# STM32U5A9 register map
File version: 1.7
CPU: CM33 r0p1, little endian, MPU, FPU, 4 interrupt priority bits
Registers are 32-bit, read-write, reset 0x0 unless marked. A register's access mark holds for its fields unless they carry their own. Offsets are from the block's base; [hi:lo] are bit positions; {n}, {i} and the like mark numbered series; 'fields as' and 'values as' point back to an identical list.

## RCC (part 1 of 2) — Reset and clock control
Base 0x46020C00
Same registers: SEC_RCC 0x56020C00
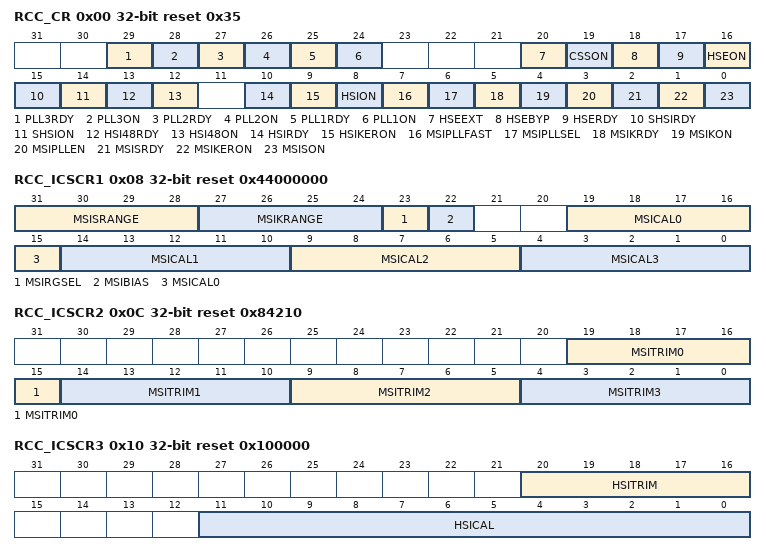
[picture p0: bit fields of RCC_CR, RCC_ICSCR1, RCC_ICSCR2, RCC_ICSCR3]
0x00 RCC_CR access per field reset 0x35 — RCC clock control register
  [29] PLL3RDY ro — PLL3 clock ready flag
    0=PLL3 unlocked; 1=PLL3 locked
  [28] PLL3ON rw — PLL3 enable
    0=PLL3 OFF; 1=PLL3 ON
  [27] PLL2RDY ro — PLL2 clock ready flag
    0=PLL2 unlocked; 1=PLL2 locked
  [26] PLL2ON rw — PLL2 enable
    0=PLL2 OFF; 1=PLL2 ON
  [25] PLL1RDY ro — PLL1 clock ready flag
    0=PLL1 unlocked; 1=PLL1 locked
  [24] PLL1ON rw — PLL1 enable
    0=PLL1 OFF; 1=PLL1 ON
  [20] HSEEXT rw — HSE external clock bypass mode
    0=external HSE clock analog mode; 1=external HSE clock digital mode (through I/O Schmitt trigger)
  [19] CSSON rw — Clock security system enable
    0=clock security system OFF (clock detector OFF); 1=clock security system ON (clock detector ON if the HSE oscillator is stable, OFF if not)
  [18] HSEBYP rw — HSE crystal oscillator bypass
    0=HSE crystal oscillator not bypassed; 1=HSE crystal oscillator bypassed with external clock
  [17] HSERDY ro — HSE clock ready flag
    0=HSE oscillator not ready; 1=HSE oscillator ready
  [16] HSEON rw — HSE clock enable
    0=HSE oscillator off; 1=HSE oscillator on
  [15] SHSIRDY ro — SHSI clock ready flag
    0=SHSI oscillator not ready; 1=SHSI oscillator ready
  [14] SHSION rw — SHSI clock enable
    0=SHSI oscillator off; 1=SHSI oscillator on
  [13] HSI48RDY ro — HSI48 clock ready flag
    0=HSI48 oscillator not ready; 1=HSI48 oscillator ready
  [12] HSI48ON rw — HSI48 clock enable
    0=HSI48 oscillator off; 1=HSI48 oscillator on
  [10] HSIRDY ro — HSI16 clock ready flag
    0=HSI16 oscillator not ready; 1=HSI16 oscillator ready
  [9] HSIKERON rw — HSI16 enable for some peripheral kernels
    0=No effect on HSI16 oscillator; 1=HSI16 oscillator forced on even in Stop mode
  [8] HSION rw — HSI16 clock enable
    0=HSI16 oscillator off; 1=HSI16 oscillator on
  [7] MSIPLLFAST rw — MSI PLL mode fast startup
    0=MSI PLL normal start-up; 1=MSI PLL fast start-up
  [6] MSIPLLSEL rw — MSI clock with PLL mode selection
    0=PLL mode applied to MSIK (MSI kernel) clock output; 1=PLL mode applied to MSIS (MSI system) clock output
  [5] MSIKRDY ro — MSIK clock ready flag
    0=MSIK (MSI kernel) oscillator not ready; 1=MSIK (MSI kernel) oscillator ready
  [4] MSIKON rw — MSIK clock enable
    0=MSIK (MSI kernel) oscillator disabled; 1=MSIK (MSI kernel) oscillator enabled
  [3] MSIPLLEN rw — MSI clock PLL-mode enable
    0=MSI PLL-mode OFF; 1=MSI PLL-mode ON
  [2] MSISRDY ro — MSIS clock ready flag
    0=MSIS (MSI system) oscillator not ready; 1=MSIS (MSI system) oscillator ready
  [1] MSIKERON rw — MSI enable for some peripheral kernels
    0=No effect on MSI oscillator; 1=MSI oscillator forced ON even in Stop mode
  [0] MSISON rw — MSIS clock enable
    0=MSIS (MSI system) oscillator off; 1=MSIS (MSI system) oscillator on
0x08 RCC_ICSCR1 access per field reset 0x44000000 (reset mask 0xFFF00000) — RCC internal clock sources calibration register 1
  [31:28] MSISRANGE rw — MSIS clock ranges
    0=range 0 around 48 MHz; 1=range 1 around 24 MHz; 2=range 2 around 16 MHz; 3=range 3 around 12 MHz; 4=range 4 around 4 MHz (reset value); 5=range 5 around 2 MHz; 6=range 6 around 1.33 MHz; 7=range 7 around 1 MHz; 8=range 8 around 3.072 MHz; 9=range 9 around 1.536 MHz; 10=range 10 around 1.024 MHz; 11=range 11 around 768 kHz; 12=range 12 around 400 kHz; 13=range 13 around 200 kHz; 14=range 14 around 133 kHz; 15=range 15 around 100 kHz
  [27:24] MSIKRANGE rw — MSIK clock ranges
    values as MSISRANGE
  [23] MSIRGSEL rw — MSI clock range selection
    0=MSIS/MSIK ranges provided by MSISSRANGE[3:0] and MSIKSRANGE[3:0] in RCC_CSR; 1=MSIS/MSIK ranges provided by MSISRANGE[3:0] and MSIKRANGE[3:0] in RCC_ICSCR1
  [22] MSIBIAS rw — MSI bias mode selection
    0=MSI bias continuous mode (clock accuracy fast settling time); 1=MSI bias sampling mode when the regulator is in range 4, or when the device is in Stop 1 or Stop 2 (ultra-low-power mode)
  [19-5n:15-5n] MSICAL{n} ro (n=0..3) — MSIRC{n} clock calibration for MSI ranges {4n} to {4n+3}
0x0C RCC_ICSCR2 reset 0x84210 — RCC internal clock sources calibration register 2
  [19-5n:15-5n] MSITRIM{n} (n=0..3) — MSI clock trimming for ranges {4n} to {4n+3}
0x10 RCC_ICSCR3 access per field reset 0x100000 (reset mask 0xFFFFF000) — RCC internal clock sources calibration register 3
  [20:16] HSITRIM rw — HSI clock trimming
  [11:0] HSICAL ro — HSI clock calibration
0x14 RCC_CRRCR ro (reset mask 0xFFFFF000) — RCC clock recovery RC register
  [8:0] HSI48CAL — HSI48 clock calibration
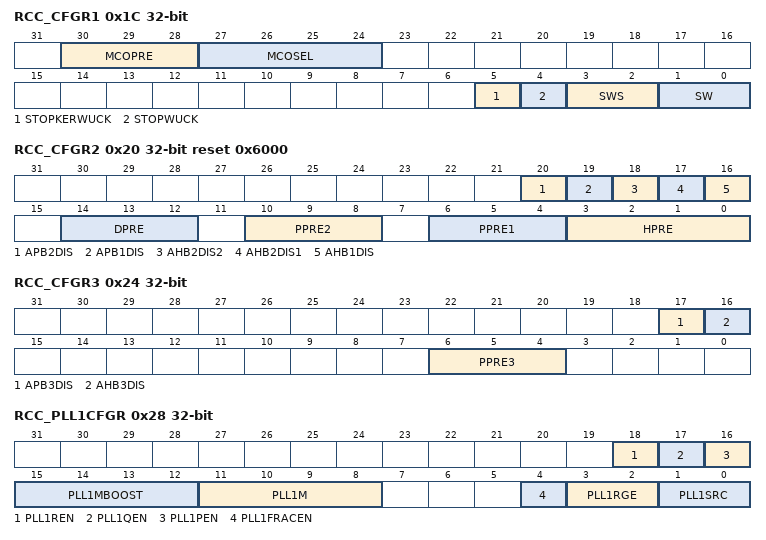
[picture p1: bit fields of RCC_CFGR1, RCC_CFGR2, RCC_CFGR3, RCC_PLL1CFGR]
0x1C RCC_CFGR1 access per field — RCC clock configuration register 1
  [30:28] MCOPRE rw — microcontroller clock output prescaler
    0=MCO divided by 1; 1=MCO divided by 2; 2=MCO divided by 4; 3=MCO divided by 8; 4=MCO divided by 16
  [27:24] MCOSEL rw — microcontroller clock output
    0=MCO output disabled, no clock on MCO; 1=SYSCLK system clock selected; 2=MSIS clock selected; 3=HSI16 clock selected; 4=HSE clock selected; 5=Main PLL clock pll1_r_ck selected; 6=LSI clock selected; 7=LSE clock selected; 8=Internal HSI48 clock selected; 9=MSIK clock selected
  [5] STOPKERWUCK rw — wake-up from Stop kernel clock automatic enable selection
    0=MSIK oscillator automatically enabled when exiting Stop mode; 1=HSI16 oscillator automatically enabled when exiting Stop mode
  [4] STOPWUCK rw — wake-up from Stop and CSS backup clock selection
    0=MSIS oscillator selected as wake-up from stop clock and CSS backup clock; 1=HSI16 oscillator selected as wake-up from stop clock and CSS backup clock
  [3:2] SWS ro — system clock switch status
    0=MSIS oscillator used as system clock; 1=HSI16 oscillator used as system clock; 2=HSE used as system clock; 3=PLL pll1_r_ck used as system clock
  [1:0] SW rw — system clock switch
    0=MSIS selected as system clock; 1=HSI16 selected as system clock; 2=HSE selected as system clock; 3=PLL pll1_r_ck selected as system clock
0x20 RCC_CFGR2 reset 0x6000 — RCC clock configuration register 2
  [20] APB2DIS — APB2 clock disable
    0=APB2 clock enabled, distributed to peripherals according to their dedicated clock enable control bits; 1=APB2 clock disabled
  [19] APB1DIS — APB1 clock disable
    0=APB1 clock enabled, distributed to peripherals according to their dedicated clock enable control bits; 1=APB1 clock disabled
  [18] AHB2DIS2 — AHB2_2 clock disable
    0=AHB2_2 clock enabled, distributed to peripherals according to their dedicated clock enable control bits; 1=AHB2_2 clock disabled
  [17] AHB2DIS1 — AHB2_1 clock disable
    0=AHB2_1 clock enabled, distributed to peripherals according to their dedicated clock enable control bits; 1=AHB2_1 clock disabled
  [16] AHB1DIS — AHB1 clock disable
    0=AHB1 clock enabled, distributed to peripherals according to their dedicated clock enable control bits; 1=AHB1 clock disabled
  [14:12] DPRE — DSI PHY prescaler
    4=DCLK divided by 2; 5=DCLK divided by 4; 6=DCLK divided by 8; 7=DCLK divided by 16
  [10:8] PPRE2 — APB2 prescaler
    4=PCLK2 divided by 2; 5=PCLK2 divided by 4; 6=PCLK2 divided by 8; 7=PCLK2 divided by 16
  [6:4] PPRE1 — APB1 prescaler
    4=PCLK1 divided by 2; 5=PCLK1 divided by 4; 6=PCLK1 divided by 8; 7=PCLK1 divided by 16
  [3:0] HPRE — AHB prescaler
    8=SYSCLK divided by 2; 9=SYSCLK divided by 4; 10=SYSCLK divided by 8; 11=SYSCLK divided by 16; 12=SYSCLK divided by 64; 13=SYSCLK divided by 128; 14=SYSCLK divided by 256; 15=SYSCLK divided by 512
0x24 RCC_CFGR3 — RCC clock configuration register 3
  [17] APB3DIS — APB3 clock disable
    0=APB3 clock enabled, distributed to peripherals according to their dedicated clock enable control bits; 1=APB3 clock disabled
  [16] AHB3DIS — AHB3 clock disable
    0=AHB3 clock enabled, distributed to peripherals according to their dedicated clock enable control bits; 1=AHB3 clock disabled
  [6:4] PPRE3 — APB3 prescaler
    4=HCLK divided by 2; 5=HCLK divided by 4; 6=HCLK divided by 8; 7=HCLK divided by 16
0x28 RCC_PLL1CFGR — RCC PLL1 configuration register
  [18] PLL1REN — PLL1 DIVR divider output enable
    0=pll1_r_ck output disabled; 1=pll1_r_ck output enabled
  [17] PLL1QEN — PLL1 DIVQ divider output enable
    0=pll1_q_ck output disabled; 1=pll1_q_ck output enabled
  [16] PLL1PEN — PLL1 DIVP divider output enable
    0=pll1_p_ck output disabled; 1=pll1_p_ck output enabled
  [15:12] PLL1MBOOST — Prescaler for EPOD booster input clock
    0=division by 1 (bypass); 1=division by 2; 2=division by 4; 3=division by 6; 4=division by 8; 5=division by 10; 6=division by 12; 7=division by 14; 8=division by 16
  [11:8] PLL1M — Prescaler for PLL1
    0=division by 1 (bypass); 1=division by 2; 2=division by 3; 15=division by 16
  [4] PLL1FRACEN — PLL1 fractional latch enable
  [3:2] PLL1RGE — PLL1 input frequency range
    3=PLL1 input (ref1_ck) clock range frequency between 8 and 16 MHz
  [1:0] PLL1SRC — PLL1 entry clock source
    0=No clock sent to PLL1; 1=MSIS clock selected as PLL1 clock entry; 2=HSI16 clock selected as PLL1 clock entry; 3=HSE clock selected as PLL1 clock entry
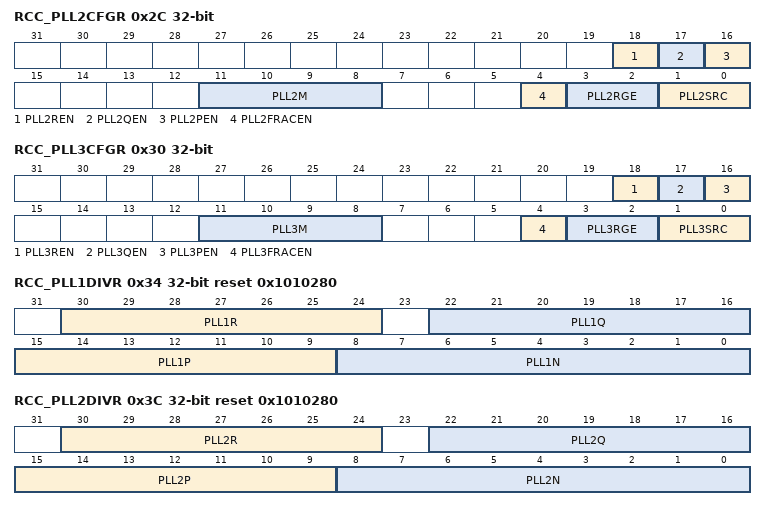
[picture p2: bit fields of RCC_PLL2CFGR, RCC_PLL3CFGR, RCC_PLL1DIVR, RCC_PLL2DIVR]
0x2C RCC_PLL2CFGR — RCC PLL2 configuration register
  [18] PLL2REN — PLL2 DIVR divider output enable
    0=pll2_r_ck output disabled; 1=pll2_r_ck output enabled
  [17] PLL2QEN — PLL2 DIVQ divider output enable
    0=pll2_q_ck output disabled; 1=pll2_q_ck output enabled
  [16] PLL2PEN — PLL2 DIVP divider output enable
    0=pll2_p_ck output disabled; 1=pll2_p_ck output enabled
  [11:8] PLL2M — Prescaler for PLL2
    values as RCC_PLL1CFGR.PLL1M
  [4] PLL2FRACEN — PLL2 fractional latch enable
  [3:2] PLL2RGE — PLL2 input frequency range
    3=PLL2 input (ref2_ck) clock range frequency between 8 and 16 MHz
  [1:0] PLL2SRC — PLL2 entry clock source
    0=No clock sent to PLL2; 1=MSIS clock selected as PLL2 clock entry; 2=HSI16 clock selected as PLL2 clock entry; 3=HSE clock selected as PLL2 clock entry
0x30 RCC_PLL3CFGR — RCC PLL3 configuration register
  [18] PLL3REN — PLL3 DIVR divider output enable
    0=pll3_r_ck output disabled; 1=pll3_r_ck output enabled
  [17] PLL3QEN — PLL3 DIVQ divider output enable
    0=pll3_q_ck output disabled; 1=pll3_q_ck output enabled
  [16] PLL3PEN — PLL3 DIVP divider output enable
    0=pll3_p_ck output disabled; 1=pll3_p_ck output enabled
  [11:8] PLL3M — Prescaler for PLL3
    values as RCC_PLL1CFGR.PLL1M
  [4] PLL3FRACEN — PLL3 fractional latch enable
  [3:2] PLL3RGE — PLL3 input frequency range
    3=PLL3 input (ref3_ck) clock range frequency between 8 and 16 MHz
  [1:0] PLL3SRC — PLL3 entry clock source
    0=No clock sent to PLL3; 1=MSIS clock selected as PLL3 clock entry; 2=HSI16 clock selected as PLL3 clock entry; 3=HSE clock selected as PLL3 clock entry
0x34 RCC_PLL1DIVR reset 0x1010280 — RCC PLL1 dividers register
  [30:24] PLL1R — PLL1 DIVR division factor
    0=Not allowed; 1=pll1_r_ck = vco1_ck / 2 (default after reset); 2=pll1_r_ck = vco1_ck / 3; 3=pll1_r_ck = vco1_ck / 4; 127=pll1_r_ck = vco1_ck / 128
  [22:16] PLL1Q — PLL1 DIVQ division factor
    0=pll1_q_ck = vco1_ck; 1=pll1_q_ck = vco1_ck / 2 (default after reset); 2=pll1_q_ck = vco1_ck / 3; 3=pll1_q_ck = vco1_ck / 4; 127=pll1_q_ck = vco1_ck / 128
  [15:9] PLL1P — PLL1 DIVP division factor
    0=Not allowed; 1=pll1_p_ck = vco1_ck / 2 (default after reset); 2=pll1_p_ck = vco1_ck; 3=pll1_p_ck = vco1_ck / 4; 127=pll1_p_ck = vco1_ck / 128
  [8:0] PLL1N — Multiplication factor for PLL1 VCO
    3=PLL1N = 4; 4=PLL1N = 5; 5=PLL1N = 6; 128=PLL1N = 129 (default after reset); 0x1FF=PLL1N = 512
{0x30+8i} RCC_PLL{i}FRACR (i=1..3) — RCC PLL{i} fractional divider register
  [15:3] PLL{i}FRACN — Fractional part of the multiplication factor for PLL{i} VCO
0x3C RCC_PLL2DIVR reset 0x1010280 — RCC PLL2 dividers configuration register
  [30:24] PLL2R — PLL2 DIVR division factor
    0=pll2_r_ck = vco2_ck; 1=pll2_r_ck = vco2_ck / 2 (default after reset); 2=pll2_r_ck = vco2_ck / 3; 3=pll2_r_ck = vco2_ck / 4; 127=pll2_r_ck = vco2_ck / 128
  [22:16] PLL2Q — PLL2 DIVQ division factor
    0=pll2_q_ck = vco2_ck; 1=pll2_q_ck = vco2_ck / 2 (default after reset); 2=pll2_q_ck = vco2_ck / 3; 3=pll2_q_ck = vco2_ck / 4; 127=pll2_q_ck = vco2_ck / 128
  [15:9] PLL2P — PLL2 DIVP division factor
    0=pll2_p_ck = vco2_ck; 1=pll2_p_ck = vco2_ck / 2 (default after reset); 2=pll2_p_ck = vco2_ck / 3; 3=pll2_p_ck = vco2_ck / 4; 127=pll2_p_ck = vco2_ck / 128
  [8:0] PLL2N — Multiplication factor for PLL2 VCO
    3=PLL2N = 4; 4=PLL2N = 5; 5=PLL2N = 6; 128=PLL2N = 129 (default after reset); 0x1FF=PLL2N = 512
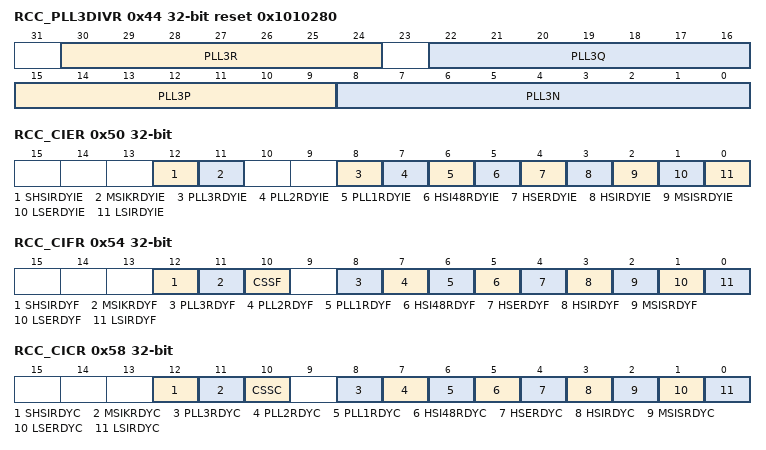
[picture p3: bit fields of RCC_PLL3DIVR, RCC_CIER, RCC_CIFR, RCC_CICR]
0x44 RCC_PLL3DIVR reset 0x1010280 — RCC PLL3 dividers configuration register
  [30:24] PLL3R — PLL3 DIVR division factor
    0=pll3_r_ck = vco3_ck; 1=pll3_r_ck = vco3_ck / 2 (default after reset); 2=pll3_r_ck = vco3_ck / 3; 3=pll3_r_ck = vco3_ck / 4; 127=pll3_r_ck = vco3_ck / 128
  [22:16] PLL3Q — PLL3 DIVQ division factor
    0=pll3_q_ck = vco3_ck; 1=pll3_q_ck = vco3_ck / 2 (default after reset); 2=pll3_q_ck = vco3_ck / 3; 3=pll3_q_ck = vco3_ck / 4; 127=pll3_q_ck = vco3_ck / 128
  [15:9] PLL3P — PLL3 DIVP division factor
    0=pll3_p_ck = vco3_ck; 1=pll3_p_ck = vco3_ck / 2 (default after reset); 2=pll3_p_ck = vco3_ck / 3; 3=pll3_p_ck = vco3_ck / 4; 127=pll3_p_ck = vco3_ck / 128
  [8:0] PLL3N — Multiplication factor for PLL3 VCO
    3=PLL3N = 4; 4=PLL3N = 5; 5=PLL3N = 6; 128=PLL3N = 129 (default after reset); 0x1FF=PLL3N = 512
0x50 RCC_CIER — RCC clock interrupt enable register
  [12] SHSIRDYIE — SHSI ready interrupt enable
    0=SHSI ready interrupt disabled; 1=SHSI ready interrupt enabled
  [11] MSIKRDYIE — MSIK ready interrupt enable
    0=MSIK ready interrupt disabled; 1=MSIK ready interrupt enabled
  [8] PLL3RDYIE — PLL3 ready interrupt enable
    0=PLL3 lock interrupt disabled; 1=PLL3 lock interrupt enabled
  [7] PLL2RDYIE — PLL2 ready interrupt enable
    0=PLL2 lock interrupt disabled; 1=PLL2 lock interrupt enabled
  [6] PLL1RDYIE — PLL ready interrupt enable
    0=PLL1 lock interrupt disabled; 1=PLL1 lock interrupt enabled
  [5] HSI48RDYIE — HSI48 ready interrupt enable
    0=HSI48 ready interrupt disabled; 1=HSI48 ready interrupt enabled
  [4] HSERDYIE — HSE ready interrupt enable
    0=HSE ready interrupt disabled; 1=HSE ready interrupt enabled
  [3] HSIRDYIE — HSI16 ready interrupt enable
    0=HSI16 ready interrupt disabled; 1=HSI16 ready interrupt enabled
  [2] MSISRDYIE — MSIS ready interrupt enable
    0=MSIS ready interrupt disabled; 1=MSIS ready interrupt enabled
  [1] LSERDYIE — LSE ready interrupt enable
    0=LSE ready interrupt disabled; 1=LSE ready interrupt enabled
  [0] LSIRDYIE — LSI ready interrupt enable
    0=LSI ready interrupt disabled; 1=LSI ready interrupt enabled
0x54 RCC_CIFR ro — RCC clock interrupt flag register
  [12] SHSIRDYF — SHSI ready interrupt flag
    0=No clock ready interrupt caused by the SHSI oscillator; 1=Clock ready interrupt caused by the SHSI oscillator
  [11] MSIKRDYF — MSIK ready interrupt flag
    0=No clock ready interrupt caused by the MSIK oscillator; 1=Clock ready interrupt caused by the MSIK oscillator
  [10] CSSF — Clock security system interrupt flag
    0=No clock security interrupt caused by HSE clock failure; 1=Clock security interrupt caused by HSE clock failure
  [8] PLL3RDYF — PLL3 ready interrupt flag
    0=No clock ready interrupt caused by PLL3 lock; 1=Clock ready interrupt caused by PLL3 lock
  [7] PLL2RDYF — PLL2 ready interrupt flag
    0=No clock ready interrupt caused by PLL2 lock; 1=Clock ready interrupt caused by PLL2 lock
  [6] PLL1RDYF — PLL1 ready interrupt flag
    0=No clock ready interrupt caused by PLL1 lock; 1=Clock ready interrupt caused by PLL1 lock
  [5] HSI48RDYF — HSI48 ready interrupt flag
    0=No clock ready interrupt caused by the HSI48 oscillator; 1=Clock ready interrupt caused by the HSI48 oscillator
  [4] HSERDYF — HSE ready interrupt flag
    0=No clock ready interrupt caused by the HSE oscillator; 1=Clock ready interrupt caused by the HSE oscillator
  [3] HSIRDYF — HSI16 ready interrupt flag
    0=No clock ready interrupt caused by the HSI16 oscillator; 1=Clock ready interrupt caused by the HSI16 oscillator
  [2] MSISRDYF — MSIS ready interrupt flag
    0=No clock ready interrupt caused by the MSIS oscillator; 1=Clock ready interrupt caused by the MSIS oscillator
  [1] LSERDYF — LSE ready interrupt flag
    0=No clock ready interrupt caused by the LSE oscillator; 1=Clock ready interrupt caused by the LSE oscillator
  [0] LSIRDYF — LSI ready interrupt flag
    0=No clock ready interrupt caused by the LSI oscillator; 1=Clock ready interrupt caused by the LSI oscillator
0x58 RCC_CICR wo — RCC clock interrupt clear register
  [12] SHSIRDYC — SHSI oscillator ready interrupt clear
  [11] MSIKRDYC — MSIK oscillator ready interrupt clear
  [10] CSSC — Clock security system interrupt clear
  [8] PLL3RDYC — PLL3 ready interrupt clear
  [7] PLL2RDYC — PLL2 ready interrupt clear
  [6] PLL1RDYC — PLL1 ready interrupt clear
  [5] HSI48RDYC — HSI48 ready interrupt clear
  [4] HSERDYC — HSE ready interrupt clear
  [3] HSIRDYC — HSI16 ready interrupt clear
  [2] MSISRDYC — MSIS ready interrupt clear
  [1] LSERDYC — LSE ready interrupt clear
  [0] LSIRDYC — LSI ready interrupt clear
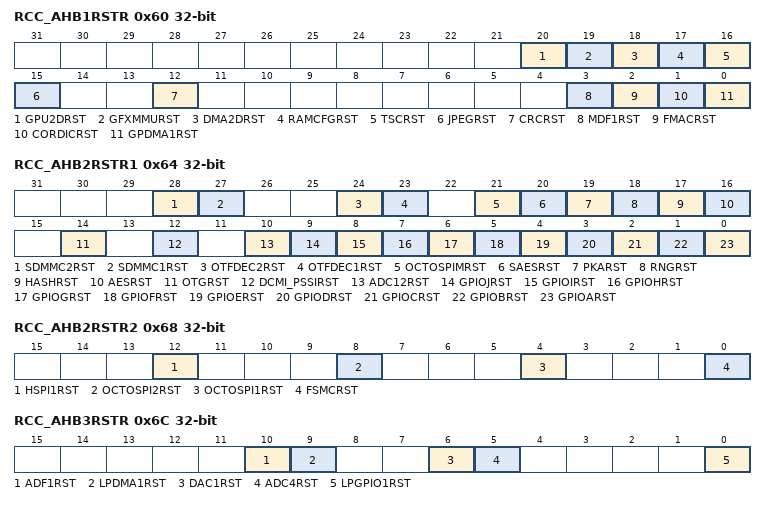
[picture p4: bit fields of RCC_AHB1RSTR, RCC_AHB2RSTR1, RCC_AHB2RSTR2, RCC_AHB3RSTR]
0x60 RCC_AHB1RSTR — RCC AHB1 peripheral reset register
  [20] GPU2DRST — GPU2D reset
    0=No effect; 1=Reset the GPU2D
  [19] GFXMMURST — GFXMMU reset
    0=No effect; 1=Reset the GFXMMU
  [18] DMA2DRST — DMA2D reset
    0=No effect; 1=Reset the DMA2D
  [17] RAMCFGRST — RAMCFG reset
    0=No effect; 1=Reset the RAMCFG
  [16] TSCRST — TSC reset
    0=No effect; 1=Reset the TSC
  [15] JPEGRST — JPEG reset
    0=No effect; 1=Reset the JPEG
  [12] CRCRST — CRC reset
    0=No effect; 1=Reset the CRC
  [3] MDF1RST — MDF1 reset
    0=No effect; 1=Reset the MDF1
  [2] FMACRST — FMAC reset
    0=No effect; 1=Reset the FMAC
  [1] CORDICRST — CORDIC reset
    0=No effect; 1=Reset the CORDIC
  [0] GPDMA1RST — GPDMA1 reset
    0=No effect; 1=Reset the GPDMA1
0x64 RCC_AHB2RSTR1 — RCC AHB2 peripheral reset register 1
  [28] SDMMC2RST — SDMMC2 reset
    0=No effect; 1=Reset the SDMMC2
  [27] SDMMC1RST — SDMMC1 reset
    0=No effect; 1=Reset the SDMMC1
  [24] OTFDEC2RST — OTFDEC2 reset
    0=No effect; 1=Reset the OTFDEC2
  [23] OTFDEC1RST — OTFDEC1 reset
    0=No effect; 1=Reset the OTFDEC1
  [21] OCTOSPIMRST — OCTOSPIM reset
    0=No effect; 1=Reset the OCTOSPIM
  [20] SAESRST — SAES hardware accelerator reset
    0=No effect; 1=Reset the SAES
  [19] PKARST — PKA reset
    0=No effect; 1=Reset the PKA
  [18] RNGRST — RNG reset
    0=No effect; 1=Reset the RNG
  [17] HASHRST — HASH reset
    0=No effect; 1=Reset the HASH
  [16] AESRST — AES hardware accelerator reset
    0=No effect; 1=Reset the AES
  [14] OTGRST — OTG_FS or OTG_HS reset
    0=No effect; 1=Reset the OTG_FS or OTG_HS
  [12] DCMI_PSSIRST — DCMI and PSSI reset
    0=No effect; 1=Reset the DCMI and PSSI
  [10] ADC12RST — ADC1 and ADC2 reset
    0=No effect; 1=Reset the ADC1 and ADC2
  [9] GPIOJRST — I/O port J reset
    0=No effect; 1=Reset the I/O port J
  [8] GPIOIRST — I/O port I reset
    0=No effect; 1=Reset the I/O port .I
  [7] GPIOHRST — I/O port H reset
    0=No effect; 1=Reset the I/O port H
  [6] GPIOGRST — I/O port G reset
    0=No effect; 1=Reset the I/O port G
  [5] GPIOFRST — I/O port F reset
    0=No effect; 1=Reset I/O port F
  [4] GPIOERST — I/O port E reset
    0=No effect; 1=Reset the I/O port E
  [3] GPIODRST — I/O port D reset
    0=No effect; 1=Reset the I/O port D
  [2] GPIOCRST — I/O port C reset
    0=No effect; 1=Reset the I/O port C
  [1] GPIOBRST — I/O port B reset
    0=No effect; 1=Reset the I/O port B
  [0] GPIOARST — I/O port A reset
    0=No effect; 1=Reset the I/O port A
0x68 RCC_AHB2RSTR2 — RCC AHB2 peripheral reset register 2
  [12] HSPI1RST — HSPI1 reset
    0=No effect; 1=Reset the HSPI1
  [8] OCTOSPI2RST — OCTOSPI2 reset
    0=No effect; 1=Reset the OCTOSPI2
  [4] OCTOSPI1RST — OCTOSPI1 reset
    0=No effect; 1=Reset the OCTOSPI1
  [0] FSMCRST — Flexible memory controller reset
    0=No effect; 1=Reset the FSMC
0x6C RCC_AHB3RSTR — RCC AHB3 peripheral reset register
  [10] ADF1RST — ADF1 reset
    0=No effect; 1=Reset the ADF1
  [9] LPDMA1RST — LPDMA1 reset
    0=No effect; 1=Reset the LPDMA1
  [6] DAC1RST — DAC1 reset
    0=No effect; 1=Reset the DAC1
  [5] ADC4RST — ADC4 reset
    0=No effect; 1=Reset the ADC4 interface
  [0] LPGPIO1RST — LPGPIO1 reset
    0=No effect; 1=Reset the LPGPIO1
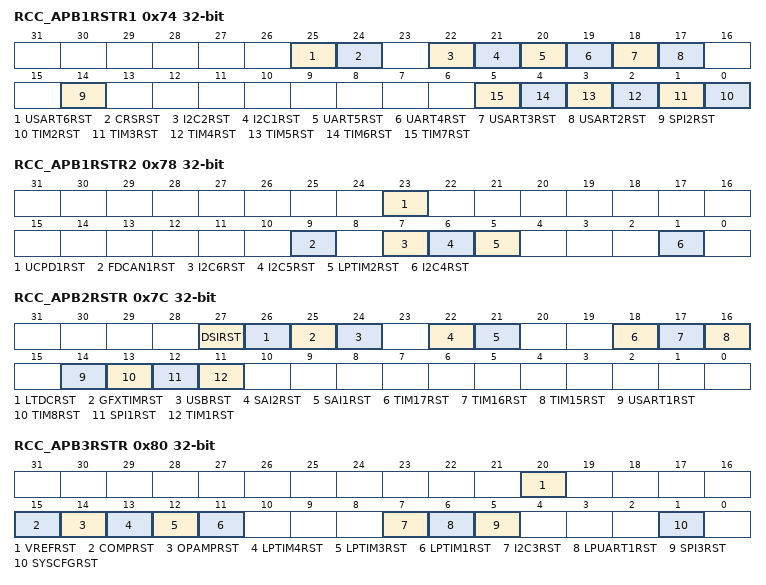
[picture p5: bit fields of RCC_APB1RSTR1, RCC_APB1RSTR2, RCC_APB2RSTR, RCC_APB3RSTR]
0x74 RCC_APB1RSTR1 — RCC APB1 peripheral reset register 1
  [25] USART6RST — USART6 reset
    0=No effect; 1=Reset the USART6
  [24] CRSRST — CRS reset
    0=No effect; 1=Reset the CRS
  [22] I2C2RST — I2C2 reset
    0=No effect; 1=Reset the I2C2
  [21] I2C1RST — I2C1 reset
    0=No effect; 1=Reset the I2C1
  [20] UART5RST — UART5 reset
    0=No effect; 1=Reset the UART5
  [19] UART4RST — UART4 reset
    0=No effect; 1=Reset the UART4
  [18] USART3RST — USART3 reset
    0=No effect; 1=Reset the USART3
  [17] USART2RST — USART2 reset
    0=No effect; 1=Reset the USART2
  [14] SPI2RST — SPI2 reset
    0=No effect; 1=Reset the SPI2
  [n-2] TIM{n}RST (n=2..7) — TIM{n} reset
    0=No effect; 1=Reset the TIM{n}
0x78 RCC_APB1RSTR2 — RCC APB1 peripheral reset register 2
  [23] UCPD1RST — UCPD1 reset
    0=No effect; 1=Reset the UCPD1
  [9] FDCAN1RST — FDCAN1 reset
    0=No effect; 1=Reset the FDCAN1
  [7] I2C6RST — I2C6 reset
    0=No effect; 1=Reset the I2C6
  [6] I2C5RST — I2C5 reset
    0=No effect; 1=Reset the I2C5
  [5] LPTIM2RST — LPTIM2 reset
    0=No effect; 1=Reset the LPTIM2
  [1] I2C4RST — I2C4 reset
    0=No effect; 1=Reset the I2C4
0x7C RCC_APB2RSTR — RCC APB2 peripheral reset register
  [27] DSIRST — DSI reset
    0=No effect; 1=Reset the DSI
  [26] LTDCRST — LTDC reset
    0=No effect; 1=Reset the LTDC
  [25] GFXTIMRST — GFXTIM reset
    0=No effect; 1=Reset the GFXTIM
  [24] USBRST — USB reset
    0=No effect; 1=Reset the USB
  [22] SAI2RST — SAI2 reset
    0=No effect; 1=Reset the SAI2
  [21] SAI1RST — SAI1 reset
    0=No effect; 1=Reset the SAI1
  [18] TIM17RST — TIM17 reset
    0=No effect; 1=Reset the TIM17
  [17] TIM16RST — TIM16 reset
    0=No effect; 1=Reset the TIM16
  [16] TIM15RST — TIM15 reset
    0=No effect; 1=Reset the TIM15
  [14] USART1RST — USART1 reset
    0=No effect; 1=Reset the USART1
  [13] TIM8RST — TIM8 reset
    0=No effect; 1=Reset the TIM8
  [12] SPI1RST — SPI1 reset
    0=No effect; 1=Reset the SPI1
  [11] TIM1RST — TIM1 reset
    0=No effect; 1=Reset the TIM1
0x80 RCC_APB3RSTR — RCC APB3 peripheral reset register
  [20] VREFRST — VREFBUF reset
    0=No effect; 1=Reset the VREFBUF
  [15] COMPRST — COMP reset
    0=No effect; 1=Reset the COMP
  [14] OPAMPRST — OPAMP reset
    0=No effect; 1=Reset the OPAMP
  [13] LPTIM4RST — LPTIM4 reset
    0=No effect; 1=Reset the LPTIM4
  [12] LPTIM3RST — LPTIM3 reset
    0=No effect; 1=Reset the LPTIM3
  [11] LPTIM1RST — LPTIM1 reset
    0=No effect; 1=Reset the LPTIM1
  [7] I2C3RST — I2C3 reset
    0=No effect; 1=Reset the I2C3
  [6] LPUART1RST — LPUART1 reset
    0=No effect; 1=Reset the LPUART1
  [5] SPI3RST — SPI3 reset
    0=No effect; 1=Reset the SPI3
  [1] SYSCFGRST — SYSCFG reset
    0=No effect; 1=Reset the SYSCFG
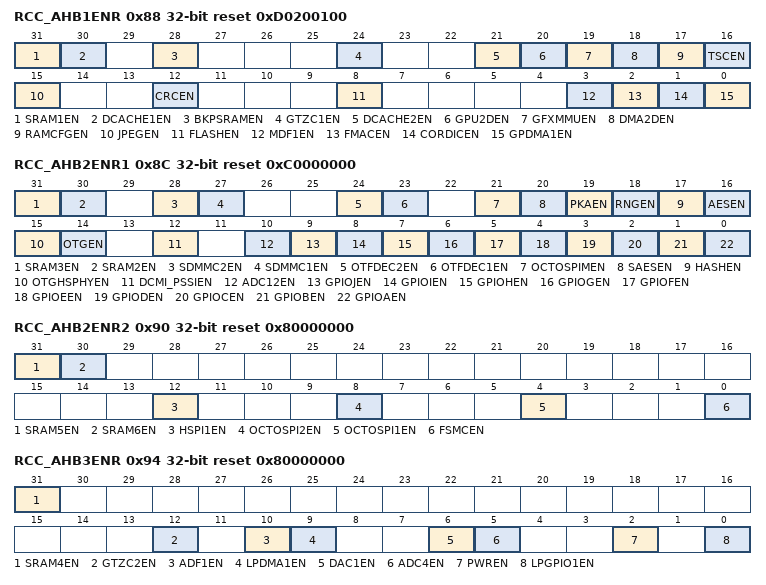
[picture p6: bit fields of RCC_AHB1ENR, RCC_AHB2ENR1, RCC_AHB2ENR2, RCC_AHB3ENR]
0x88 RCC_AHB1ENR reset 0xD0200100 — RCC AHB1 peripheral clock enable register
  [31] SRAM1EN — SRAM1 clock enable
    0=SRAM1 clock disabled; 1=SRAM1 clock enabled
  [30] DCACHE1EN — DCACHE1 clock enable
    0=DCACHE1 clock disabled; 1=DCACHE1 clock enabled
  [28] BKPSRAMEN — BKPSRAM clock enable
    0=BKPSRAM clock disabled; 1=BKPSRAM clock enabled
  [24] GTZC1EN — GTZC1 clock enable
    0=GTZC1 clock disabled; 1=GTZC1 clock enabled
  [21] DCACHE2EN — DCACHE2 clock enable
    0=DCACHE2 clock disabled; 1=DCACHE2 clock enabled
  [20] GPU2DEN — GPU2D clock enable
    0=GPU2D clock disabled; 1=GPU2D clock enabled
  [19] GFXMMUEN — GFXMMU clock enable
    0=GFXMMU clock disabled; 1=GFXMMU clock enabled
  [18] DMA2DEN — DMA2D clock enable
    0=DMA2D clock disabled; 1=DMA2D clock enabled
  [17] RAMCFGEN — RAMCFG clock enable
    0=RAMCFG clock disabled; 1=RAMCFG clock enabled
  [16] TSCEN — Touch sensing controller clock enable
    0=TSC clock disabled; 1=TSC clock enabled
  [15] JPEGEN — JPEG clock enable
    0=JPEG clock disabled; 1=JPEG clock enabled
  [12] CRCEN — CRC clock enable
    0=CRC clock disabled; 1=CRC clock enabled
  [8] FLASHEN — FLASH clock enable
    0=FLASH clock disabled; 1=FLASH clock enabled
  [3] MDF1EN — MDF1 clock enable
    0=MDF1 clock disabled; 1=MDF1 clock enabled
  [2] FMACEN — FMAC clock enable
    0=FMAC clock disabled; 1=FMAC clock enabled
  [1] CORDICEN — CORDIC clock enable
    0=CORDIC clock disabled; 1=CORDIC clock enabled
  [0] GPDMA1EN — GPDMA1 clock enable
    0=GPDMA1 clock disabled; 1=GPDMA1 clock enabled
0x8C RCC_AHB2ENR1 reset 0xC0000000 — RCC AHB2 peripheral clock enable register 1
  [31] SRAM3EN — SRAM3 clock enable
    0=SRAM3 clock disabled; 1=SRAM3 clock enabled
  [30] SRAM2EN — SRAM2 clock enable
    0=SRAM2 clock disabled; 1=SRAM2 clock enabled
  [28] SDMMC2EN — SDMMC2 clock enable
    0=SDMMC2 clock disabled; 1=SDMMC2 clock enabled
  [27] SDMMC1EN — SDMMC1 clock enable
    0=SDMMC1 clock disabled; 1=SDMMC1 clock enabled
  [24] OTFDEC2EN — OTFDEC2 clock enable
    0=OTFDEC2 clock disabled; 1=OTFDEC2 clock enabled
  [23] OTFDEC1EN — OTFDEC1 clock enable
    0=OTFDEC1 clock disabled; 1=OTFDEC1 clock enabled
  [21] OCTOSPIMEN — OCTOSPIM clock enable
    0=OCTOSPIM clock disabled; 1=OCTOSPIM clock enabled
  [20] SAESEN — SAES clock enable
    0=SAES clock disabled; 1=SAES clock enabled
  [19] PKAEN — PKA clock enable
    0=PKA clock disabled; 1=PKA clock enabled
  [18] RNGEN — RNG clock enable
    0=RNG clock disabled; 1=RNG clock enabled
  [17] HASHEN — HASH clock enable
    0=HASH clock disabled; 1=HASH clock enabled
  [16] AESEN — AES clock enable
    0=AES clock disabled; 1=AES clock enabled
  [15] OTGHSPHYEN — OTG_HS PHY clock enable
    0=OTG_HS PHY clock disabled; 1=OTG_HS PHY clock enabled
  [14] OTGEN — OTG_FS or OTG_HS clock enable
    0=OTG_FS or OTG_HS clock disabled; 1=OTG_FS or OTG_HS clock enabled
  [12] DCMI_PSSIEN — DCMI and PSSI clock enable
    0=DCMI and PSSI clock disabled; 1=DCMI and PSSI clock enabled
  [10] ADC12EN — ADC1 and ADC2 clock enable
    0=ADC1 and ADC2 clock disabled; 1=ADC1 and ADC2 clock enabled
  [9] GPIOJEN — I/O port J clock enable
    0=I/O port J clock disabled; 1=I/O port J clock enabled
  [8] GPIOIEN — I/O port I clock enable
    0=I/O port I clock disabled; 1=I/O port I clock enabled
  [7] GPIOHEN — I/O port H clock enable
    0=I/O port H clock disabled; 1=I/O port H clock enabled
  [6] GPIOGEN — I/O port G clock enable
    0=I/O port G clock disabled; 1=I/O port G clock enabled
  [5] GPIOFEN — I/O port F clock enable
    0=I/O port F clock disabled; 1=I/O port F clock enabled
  [4] GPIOEEN — I/O port E clock enable
    0=I/O port E clock disabled; 1=I/O port E clock enabled
  [3] GPIODEN — I/O port D clock enable
    0=I/O port D clock disabled; 1=I/O port D clock enabled
  [2] GPIOCEN — I/O port C clock enable
    0=I/O port C clock disabled; 1=I/O port C clock enabled
  [1] GPIOBEN — I/O port B clock enable
    0=I/O port B clock disabled; 1=I/O port B clock enabled
  [0] GPIOAEN — I/O port A clock enable
    0=I/O port A clock disabled; 1=I/O port A clock enabled
0x90 RCC_AHB2ENR2 reset 0x80000000 — RCC AHB2 peripheral clock enable register 2
  [31] SRAM5EN — SRAM5 clock enable
    0=SRAM5 clock disabled; 1=SRAM5 clock enabled
  [30] SRAM6EN — SRAM6 clock enable
    0=SRAM6 clock disabled; 1=SRAM6 clock enabled
  [12] HSPI1EN — HSPI1 clock enable
    0=HSPI1 clock disabled; 1=HSPI1 clock enabled
  [8] OCTOSPI2EN — OCTOSPI2 clock enable
    0=OCTOSPI2 clock disabled; 1=OCTOSPI2 clock enabled
  [4] OCTOSPI1EN — OCTOSPI1 clock enable
    0=OCTOSPI1 clock disabled; 1=OCTOSPI1 clock enabled
  [0] FSMCEN — FSMC clock enable
    0=FSMC clock disabled; 1=FSMC clock enabled
0x94 RCC_AHB3ENR reset 0x80000000 — RCC AHB3 peripheral clock enable register
  [31] SRAM4EN — SRAM4 clock enable
    0=SRAM4 clock disabled; 1=SRAM4 clock enabled
  [12] GTZC2EN — GTZC2 clock enable
    0=GTZC2 clock disabled; 1=GTZC2 clock enabled
  [10] ADF1EN — ADF1 clock enable
    0=ADF1 clock disabled; 1=ADF1 clock enabled
  [9] LPDMA1EN — LPDMA1 clock enable
    0=LPDMA1 clock disabled; 1=LPDMA1 clock enabled
  [6] DAC1EN — DAC1 clock enable
    0=DAC1 clock disabled; 1=DAC1 clock enabled
  [5] ADC4EN — ADC4 clock enable
    0=ADC4 clock disabled; 1=ADC4 clock enabled
  [2] PWREN — PWR clock enable
    0=PWR clock disabled; 1=PWR clock enabled
  [0] LPGPIO1EN — LPGPIO1 enable
    0=LPGPIO1 clock disabled; 1=LPGPIO1 clock enabled
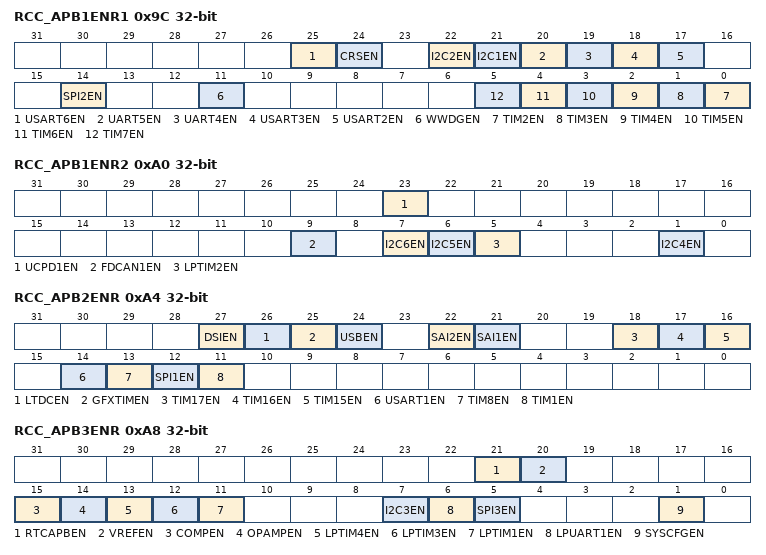
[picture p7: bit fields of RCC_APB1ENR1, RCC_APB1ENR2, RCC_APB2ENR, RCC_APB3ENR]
0x9C RCC_APB1ENR1 — RCC APB1 peripheral clock enable register 1
  [25] USART6EN — USART6 clock enable
    0=USART6 clock disabled; 1=USART6 clock enabled
  [24] CRSEN — CRS clock enable
    0=CRS clock disabled; 1=CRS clock enabled
  [22] I2C2EN — I2C2 clock enable
    0=I2C2 clock disabled; 1=I2C2 clock enabled
  [21] I2C1EN — I2C1 clock enable
    0=I2C1 clock disabled; 1=I2C1 clock enabled
  [20] UART5EN — UART5 clock enable
    0=UART5 clock disabled; 1=UART5 clock enabled
  [19] UART4EN — UART4 clock enable
    0=UART4 clock disabled; 1=UART4 clock enabled
  [18] USART3EN — USART3 clock enable
    0=USART3 clock disabled; 1=USART3 clock enabled
  [17] USART2EN — USART2 clock enable
    0=USART2 clock disabled; 1=USART2 clock enabled
  [14] SPI2EN — SPI2 clock enable
    0=SPI2 clock disabled; 1=SPI2 clock enabled
  [11] WWDGEN — WWDG clock enable
    0=WWDG clock disabled; 1=WWDG clock enabled
  [n-2] TIM{n}EN (n=2..7) — TIM{n} clock enable
    0=TIM{n} clock disabled; 1=TIM{n} clock enabled
0xA0 RCC_APB1ENR2 — RCC APB1 peripheral clock enable register 2
  [23] UCPD1EN — UCPD1 clock enable
    0=UCPD1 clock disabled; 1=UCPD1 clock enabled
  [9] FDCAN1EN — FDCAN1 clock enable
    0=FDCAN1 clock disabled; 1=FDCAN1 clock enabled
  [7] I2C6EN — I2C6 clock enable
    0=I2C6 clock disabled; 1=I2C6 clock enabled
  [6] I2C5EN — I2C5 clock enable
    0=I2C5 clock disabled; 1=I2C5 clock enabled
  [5] LPTIM2EN — LPTIM2 clock enable
    0=LPTIM2 clock disabled; 1=LPTIM2 clock enabled
  [1] I2C4EN — I2C4 clock enable
    0=I2C4 clock disabled; 1=I2C4 clock enabled
0xA4 RCC_APB2ENR — RCC APB2 peripheral clock enable register
  [27] DSIEN — DSI clock enable
    0=DSI clock disabled; 1=DSI clock enabled
  [26] LTDCEN — LTDC clock enable
    0=LTDC clock disabled; 1=LTDC clock enabled
  [25] GFXTIMEN — GFXTIM clock enable
    0=GFXTIM clock disabled; 1=GFXTIM clock enabled
  [24] USBEN — USB clock enable
    0=USB clock disabled; 1=USB clock enabled
  [22] SAI2EN — SAI2 clock enable
    0=SAI2 clock disabled; 1=SAI2 clock enabled
  [21] SAI1EN — SAI1 clock enable
    0=SAI1 clock disabled; 1=SAI1 clock enabled
  [18] TIM17EN — TIM17 clock enable
    0=TIM17 clock disabled; 1=TIM17 clock enabled
  [17] TIM16EN — TIM16 clock enable
    0=TIM16 clock disabled; 1=TIM16 clock enabled
  [16] TIM15EN — TIM15 clock enable
    0=TIM15 clock disabled; 1=TIM15 clock enabled
  [14] USART1EN — USART1clock enable
    0=USART1 clock disabled; 1=USART1 clock enabled
  [13] TIM8EN — TIM8 clock enable
    0=TIM8 clock disabled; 1=TIM8 clock enabled
  [12] SPI1EN — SPI1 clock enable
    0=SPI1 clock disabled; 1=SPI1 clock enabled
  [11] TIM1EN — TIM1 clock enable
    0=TIM1 clock disabled; 1=TIM1 clock enabled
0xA8 RCC_APB3ENR — RCC APB3 peripheral clock enable register
  [21] RTCAPBEN — RTC and TAMP APB clock enable
    0=RTC and TAMP APB clock disabled; 1=RTC and TAMP APB clock enabled
  [20] VREFEN — VREFBUF clock enable
    0=VREFBUF clock disabled; 1=VREFBUF clock enabled
  [15] COMPEN — COMP clock enable
    0=COMP clock disabled; 1=COMP clock enabled
  [14] OPAMPEN — OPAMP clock enable
    0=OPAMP clock disabled; 1=OPAMP clock enabled
  [13] LPTIM4EN — LPTIM4 clock enable
    0=LPTIM4 clock disabled; 1=LPTIM4 clock enabled
  [12] LPTIM3EN — LPTIM3 clock enable
    0=LPTIM3 clock disabled; 1=LPTIM3 clock enabled
  [11] LPTIM1EN — LPTIM1 clock enable
    0=LPTIM1 clock disabled; 1=LPTIM1 clock enabled
  [7] I2C3EN — I2C3 clock enable
    0=I2C3 clock disabled; 1=I2C3 clock enabled
  [6] LPUART1EN — LPUART1 clock enable
    0=LPUART1 clock disabled; 1=LPUART1 clock enabled
  [5] SPI3EN — SPI3 clock enable
    0=SPI3 clock disabled; 1=SPI3 clock enabled
  [1] SYSCFGEN — SYSCFG clock enable
    0=SYSCFG clock disabled; 1=SYSCFG clock enabled
